AUTOSAR XML (schema 4-2-2)
standard types defined: boolean, float32, float64, uint16, uint32, uint64, uint8
package /DataTypes
  base type bool: category=FIXED_LENGTH, base-type-size=8, base-type-encoding=BOOLEAN, native-declaration=boolean
  impl type bool_impl: category=VALUE, base-type=bool
  impl type boolean_impl: category=VALUE, base-type=boolean
  impl type float32_impl: category=VALUE, base-type=float32
  impl type float64_impl: category=VALUE, base-type=float64
  base type int16: category=FIXED_LENGTH, base-type-size=16, base-type-encoding=2C, native-declaration=int16_t
  impl type int16_impl: category=VALUE, base-type=int16
  base type int32: category=FIXED_LENGTH, base-type-size=32, base-type-encoding=2C, native-declaration=int32_t
  impl type int32_impl: category=VALUE, base-type=int32
  base type int64: category=FIXED_LENGTH, base-type-size=64, base-type-encoding=2C, native-declaration=int64_t
  impl type int64_impl: category=VALUE, base-type=int64
  base type int8: category=FIXED_LENGTH, base-type-size=8, base-type-encoding=2C, native-declaration=int8_t
  impl type int8_impl: category=VALUE, base-type=int8
  impl type uint16_impl: category=VALUE, base-type=uint16
  impl type uint32_impl: category=VALUE, base-type=uint32
  impl type uint64_impl: category=VALUE, base-type=uint64
  impl type uint8_impl: category=VALUE, base-type=uint8
package /PortInterfaces
  client server interface IDiagnosticService
    operation ReadDtc
      arg dtc_id: type=uint16_impl, direction=IN, server-argument-impl-policy=USE-ARGUMENT-TYPE
      arg status: type=uint8_impl, direction=OUT, server-argument-impl-policy=USE-ARGUMENT-TYPE
    operation ClearDtc
      arg dtc_id: type=uint16_impl, direction=IN, server-argument-impl-policy=USE-ARGUMENT-TYPE
      arg result: type=uint8_impl, direction=OUT, server-argument-impl-policy=USE-ARGUMENT-TYPE
  sender receiver interface IExample
    data value: type=float32_impl
package /ComponentTypes
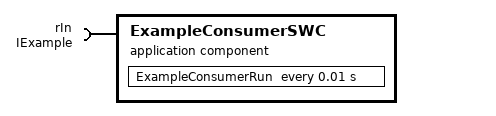
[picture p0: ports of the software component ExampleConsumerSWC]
  application sw component type ExampleConsumerSWC
    require port rIn: nonqueued-receiver-com-spec{data-element=value, filter=data-filter-type=ALWAYS}, required-interface=IExample
    behavior ExampleConsumerSWC_InternalBehavior: port-api-option{enable-take-address=false, indirect-api=false, port=rIn}
      timing event TMT_ExampleConsumerRun: start-on-event=ExampleConsumerRun, period=0.01
      runnable ExampleConsumerRun: minimum-start-interval=0.01
  swc implementation ExampleConsumerSWC_Implementation: behavior=ExampleConsumerSWC_InternalBehavior
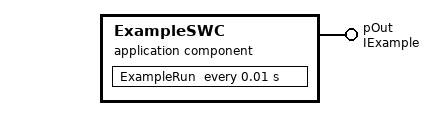
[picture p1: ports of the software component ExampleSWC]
  application sw component type ExampleSWC
    provide port pOut: nonqueued-sender-com-spec=data-element=value, provided-interface=IExample
    behavior ExampleSWC_InternalBehavior: port-api-option{enable-take-address=false, indirect-api=false, port=pOut}
      timing event TMT_ExampleRun: start-on-event=ExampleRun, period=0.01
      runnable ExampleRun: minimum-start-interval=0.01
  swc implementation ExampleSWC_Implementation: behavior=ExampleSWC_InternalBehavior
  composition sw component type SwCraftComposition
    component ExampleConsumerSWC: type=ExampleConsumerSWC
    component ExampleSWC: type=ExampleSWC
    connect ExampleSWC.pOut -> ExampleConsumerSWC.rIn
